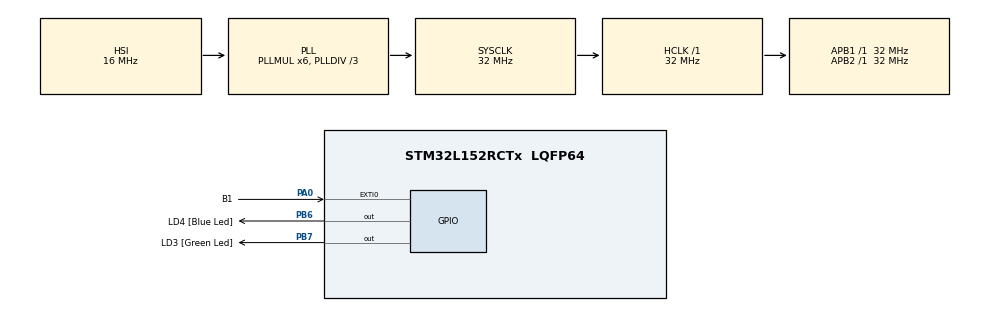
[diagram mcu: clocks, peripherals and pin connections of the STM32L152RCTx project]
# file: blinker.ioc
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Mcu.Family=STM32L1
Mcu.Name=STM32L152RCTx
Mcu.Package=LQFP64
NVIC.EXTI0_IRQn=true\:0\:0\:false\:false\:true\:true\:true
NVIC.PriorityGroup=NVIC_PRIORITYGROUP_0
NVIC.RCC_IRQn=true\:0\:0\:false\:false\:true\:true\:false
NVIC.TIM2_IRQn=true\:0\:0\:false\:false\:false\:true\:false
PA0-WKUP1.GPIO_Label=B1
PA0-WKUP1.Signal=GPXTI0
PA13.GPIO_Label=SWDIO
PA13.Mode=Serial_Wire
PA13.Signal=SYS_JTMS-SWDIO
PA14.GPIO_Label=SWCLK
PA14.Mode=Serial_Wire
PA14.Signal=SYS_JTCK-SWCLK
PB6.GPIO_Label=LD4 [Blue Led]
PB6.GPIO_ModeDefaultOutputPP=GPIO_MODE_OUTPUT_PP
PB6.GPIO_PuPd=GPIO_NOPULL
PB6.GPIO_Speed=GPIO_SPEED_FREQ_LOW
PB6.Signal=GPIO_Output
PB7.GPIO_Label=LD3 [Green Led]
PB7.GPIO_ModeDefaultOutputPP=GPIO_MODE_OUTPUT_PP
PB7.GPIO_PuPd=GPIO_NOPULL
PB7.GPIO_Speed=GPIO_SPEED_FREQ_LOW
PB7.Signal=GPIO_Output
PC14-OSC32_IN.GPIO_Label=PC14-OSC32_IN
PC14-OSC32_IN.Mode=LSE-External-Oscillator
PC14-OSC32_IN.Signal=RCC_OSC32_IN
PC15-OSC32_OUT.GPIO_Label=PC15-OSC32_OUT
PC15-OSC32_OUT.Mode=LSE-External-Oscillator
PC15-OSC32_OUT.Signal=RCC_OSC32_OUT
ProjectManager.HeapSize=0x200
ProjectManager.StackSize=0x400
ProjectManager.TargetToolchain=STM32CubeIDE
RCC.48MHZClocksFreq_Value=48000000
RCC.AHBFreq_Value=32000000
RCC.APB1Freq_Value=32000000
RCC.APB1TimFreq_Value=32000000
RCC.APB2Freq_Value=32000000
RCC.APB2TimFreq_Value=32000000
RCC.HCLKFreq_Value=32000000
RCC.HSE_VALUE=8000000
RCC.HSI_VALUE=16000000
RCC.MSI_VALUE=2097000
RCC.PLLDIV=RCC_PLL_DIV3
RCC.PLLMUL=RCC_PLL_MUL6
RCC.RTCClockSelectionVirtual=RCC_RTCCLKSOURCE_LSE
RCC.SYSCLKFreq_VALUE=32000000
RCC.SYSCLKSource=RCC_SYSCLKSOURCE_PLLCLK
RCC.USBOutput=48000000
RCC.VCOOutputFreq_Value=96000000
TIM2.AutoReloadPreload=TIM_AUTORELOAD_PRELOAD_DISABLE
TIM2.ClockDivision=TIM_CLOCKDIVISION_DIV2
TIM2.CounterMode=TIM_COUNTERMODE_UP
TIM2.Period=0x0
TIM2.Prescaler=16
VP_TIM2_VS_ClockSourceINT.Mode=Internal
board=STM32L152C-DISCO

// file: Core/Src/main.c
/* USER CODE BEGIN Header */
/**
  ******************************************************************************
  * @file           : main.c
  * @brief          : Main program body
  ******************************************************************************
  * @attention
  *
  * <h2><center>&copy; Copyright (c) 2020 STMicroelectronics.
  * All rights reserved.</center></h2>
  *
  * This software component is licensed by ST under BSD 3-Clause license,
  * the "License"; You may not use this file except in compliance with the
  * License. You may obtain a copy of the License at:
  *                        opensource.org/licenses/BSD-3-Clause
  *
  ******************************************************************************
  */
/* USER CODE END Header */
#include "main.h"

TIM_HandleTypeDef htim2;

void SystemClock_Config(void);
static void MX_GPIO_Init(void);
static void MX_TIM2_Init(void);

int main(void)
{

  /* MCU Configuration--------------------------------------------------------*/

  /* Reset of all peripherals, Initializes the Flash interface and the Systick. */
  HAL_Init();

  /* Configure the system clock */
  SystemClock_Config();

  /* Initialize all configured peripherals */
  MX_GPIO_Init();
  MX_TIM2_Init();
  /* USER CODE BEGIN 2 */
  // Настройка системы управления светодиодом
  bam_driver_init();
  /* USER CODE END 2 */

  /* Infinite loop */
  /* USER CODE BEGIN WHILE */
  bam_driver_start();
  while (1)
  {
    /* USER CODE END WHILE */

  }
}

void SystemClock_Config(void)
{
  RCC_OscInitTypeDef RCC_OscInitStruct = {0};
  RCC_ClkInitTypeDef RCC_ClkInitStruct = {0};

  /** Configure the main internal regulator output voltage
  */
  __HAL_PWR_VOLTAGESCALING_CONFIG(PWR_REGULATOR_VOLTAGE_SCALE1);
  /** Initializes the RCC Oscillators according to the specified parameters
  * in the RCC_OscInitTypeDef structure.
  */
  RCC_OscInitStruct.OscillatorType = RCC_OSCILLATORTYPE_HSI;
  RCC_OscInitStruct.HSIState = RCC_HSI_ON;
  RCC_OscInitStruct.HSICalibrationValue = RCC_HSICALIBRATION_DEFAULT;
  RCC_OscInitStruct.PLL.PLLState = RCC_PLL_ON;
  RCC_OscInitStruct.PLL.PLLSource = RCC_PLLSOURCE_HSI;
  RCC_OscInitStruct.PLL.PLLMUL = RCC_PLL_MUL6;
  RCC_OscInitStruct.PLL.PLLDIV = RCC_PLL_DIV3;
  if (HAL_RCC_OscConfig(&RCC_OscInitStruct) != HAL_OK)
  {
    Error_Handler();
  }
  /** Initializes the CPU, AHB and APB buses clocks
  */
  RCC_ClkInitStruct.ClockType = RCC_CLOCKTYPE_HCLK|RCC_CLOCKTYPE_SYSCLK
                              |RCC_CLOCKTYPE_PCLK1|RCC_CLOCKTYPE_PCLK2;
  RCC_ClkInitStruct.SYSCLKSource = RCC_SYSCLKSOURCE_PLLCLK;
  RCC_ClkInitStruct.AHBCLKDivider = RCC_SYSCLK_DIV1;
  RCC_ClkInitStruct.APB1CLKDivider = RCC_HCLK_DIV1;
  RCC_ClkInitStruct.APB2CLKDivider = RCC_HCLK_DIV1;

  if (HAL_RCC_ClockConfig(&RCC_ClkInitStruct, FLASH_LATENCY_1) != HAL_OK)
  {
    Error_Handler();
  }
}

static void MX_TIM2_Init(void)
{

  TIM_ClockConfigTypeDef sClockSourceConfig = {0};
  TIM_MasterConfigTypeDef sMasterConfig = {0};

  htim2.Instance = TIM2;
  htim2.Init.Prescaler = 16;
  htim2.Init.CounterMode = TIM_COUNTERMODE_UP;
  htim2.Init.Period = 0x0;
  htim2.Init.ClockDivision = TIM_CLOCKDIVISION_DIV2;
  htim2.Init.AutoReloadPreload = TIM_AUTORELOAD_PRELOAD_DISABLE;
  if (HAL_TIM_Base_Init(&htim2) != HAL_OK)
  {
    Error_Handler();
  }
  sClockSourceConfig.ClockSource = TIM_CLOCKSOURCE_INTERNAL;
  if (HAL_TIM_ConfigClockSource(&htim2, &sClockSourceConfig) != HAL_OK)
  {
    Error_Handler();
  }
  sMasterConfig.MasterOutputTrigger = TIM_TRGO_RESET;
  sMasterConfig.MasterSlaveMode = TIM_MASTERSLAVEMODE_DISABLE;
  if (HAL_TIMEx_MasterConfigSynchronization(&htim2, &sMasterConfig) != HAL_OK)
  {
    Error_Handler();
  }

}

static void MX_GPIO_Init(void)
{
  GPIO_InitTypeDef GPIO_InitStruct = {0};

  /* GPIO Ports Clock Enable */
  __HAL_RCC_GPIOC_CLK_ENABLE();
  __HAL_RCC_GPIOA_CLK_ENABLE();
  __HAL_RCC_GPIOB_CLK_ENABLE();

  /*Configure GPIO pin Output Level */
  HAL_GPIO_WritePin(GPIOB, LD4_Pin|LD3_Pin, GPIO_PIN_RESET);

  /*Configure GPIO pin : B1_Pin */
  GPIO_InitStruct.Pin = B1_Pin;
  GPIO_InitStruct.Mode = GPIO_MODE_IT_RISING;
  GPIO_InitStruct.Pull = GPIO_NOPULL;
  HAL_GPIO_Init(B1_GPIO_Port, &GPIO_InitStruct);

  /*Configure GPIO pins : LD4_Pin LD3_Pin */
  GPIO_InitStruct.Pin = LD4_Pin|LD3_Pin;
  GPIO_InitStruct.Mode = GPIO_MODE_OUTPUT_PP;
  GPIO_InitStruct.Pull = GPIO_NOPULL;
  GPIO_InitStruct.Speed = GPIO_SPEED_FREQ_LOW;
  HAL_GPIO_Init(GPIOB, &GPIO_InitStruct);

  /* EXTI interrupt init*/
  HAL_NVIC_SetPriority(EXTI0_IRQn, 0, 0);
  HAL_NVIC_EnableIRQ(EXTI0_IRQn);

}

void Error_Handler(void)
{
}

/************************ (C) COPYRIGHT STMicroelectronics *****END OF FILE****/
